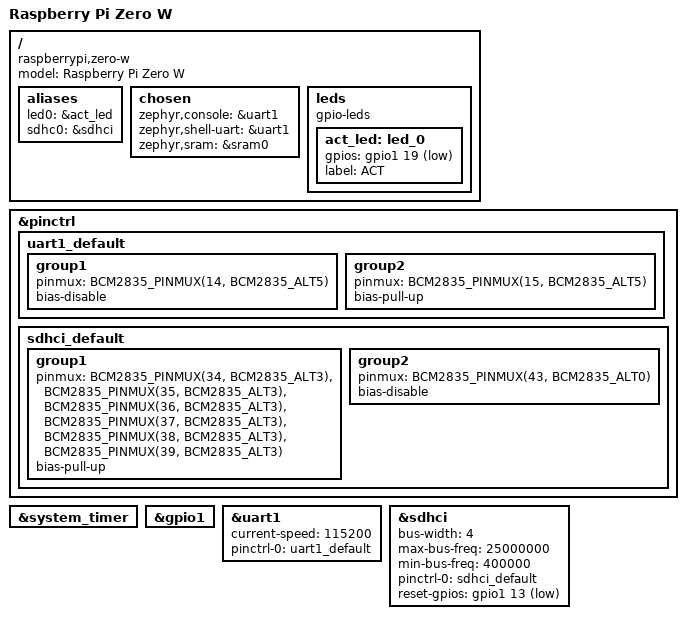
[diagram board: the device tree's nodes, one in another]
/*
 * Copyright (c) 2026
 *
 * SPDX-License-Identifier: Apache-2.0
 */

/dts-v1/;

#include <zephyr/dt-bindings/gpio/gpio.h>
#include <zephyr/dt-bindings/pinctrl/brcm-bcm2835-pinctrl.h>
#include <broadcom/bcm2835.dtsi>

/ {
	model = "Raspberry Pi Zero W";
	compatible = "raspberrypi,zero-w", "brcm,bcm2835";
	#address-cells = <1>;
	#size-cells = <1>;

	aliases {
		led0 = &act_led;
		sdhc0 = &sdhci;
	};

	chosen {
		/* Temporary minimal bring-up target: timer + mini-UART only. */
		zephyr,console = &uart1;
		zephyr,shell-uart = &uart1;
		zephyr,sram = &sram0;
	};

	leds {
		compatible = "gpio-leds";

		act_led: led_0 {
			gpios = <&gpio1 19 GPIO_ACTIVE_LOW>; /* GPIO47 */
			label = "ACT";
		};
	};
};

&pinctrl {
	uart1_default: uart1_default {
		group1 {
			pinmux = <BCM2835_PINMUX(14, BCM2835_ALT5)>;
			bias-disable;
		};

		group2 {
			pinmux = <BCM2835_PINMUX(15, BCM2835_ALT5)>;
			bias-pull-up;
		};
	};

	sdhci_default: sdhci_default {
		group1 {
			pinmux = <BCM2835_PINMUX(34, BCM2835_ALT3)>,
				 <BCM2835_PINMUX(35, BCM2835_ALT3)>,
				 <BCM2835_PINMUX(36, BCM2835_ALT3)>,
				 <BCM2835_PINMUX(37, BCM2835_ALT3)>,
				 <BCM2835_PINMUX(38, BCM2835_ALT3)>,
				 <BCM2835_PINMUX(39, BCM2835_ALT3)>;
			bias-pull-up;
		};

		group2 {
			pinmux = <BCM2835_PINMUX(43, BCM2835_ALT0)>;
			bias-disable;
		};
	};
};

&system_timer {
	status = "okay";
};

&gpio1 {
	status = "okay";
};

&uart1 {
	current-speed = <115200>;
	pinctrl-0 = <&uart1_default>;
	pinctrl-names = "default";
	status = "okay";
};

&sdhci {
	bus-width = <4>;
	max-bus-freq = <25000000>;
	min-bus-freq = <400000>;
	pinctrl-0 = <&sdhci_default>;
	pinctrl-names = "default";
	reset-gpios = <&gpio1 13 GPIO_ACTIVE_LOW>; /* GPIO41/WL_ON */
	status = "okay";
};
